AUTOSAR XML (schema 4-2-2)
package /STELLANTIS/EPT/ASWCs
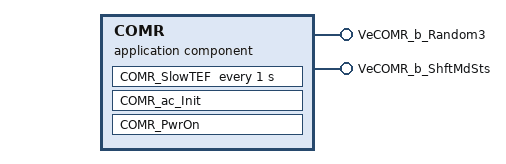
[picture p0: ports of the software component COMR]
  application sw component type COMR
    provide port VeCOMR_b_Random3: nonqueued-sender-com-spec{data-element=Value, init-value=0}, provided-interface=VeCOMR_b_Random3
    provide port VeCOMR_b_ShftMdSts: nonqueued-sender-com-spec{data-element=Value, init-value=0}, provided-interface=VeCOMR_b_ShftMdSts
    behavior IB_COMR: data-type-mapping=msADTtoIDTMapping, handle-termination-and-restart=NO-SUPPORT
      timing event Event_SlowTEF: start-on-event=COMR_SlowTEF, period=1
      init event Event_COMR_ac_Init: start-on-event=COMR_ac_Init
      init event Event_PwrOn: start-on-event=COMR_PwrOn
      runnable COMR_ac_Init
        data-send-points:
          access OUT_VeCOMR_b_ShftMdSts_Value: accessed-variable=VeCOMR_b_ShftMdSts.Value
      runnable COMR_PwrOn
        data-send-points:
          access OUT_VeCOMR_b_ShftMdSts_Value: accessed-variable=VeCOMR_b_ShftMdSts.Value
          access OUT_VeCOMR_b_Random3_Value: accessed-variable=VeCOMR_b_Random3.Value
      runnable COMR_SlowTEF
        data-send-points:
          access OUT_VeCOMR_b_Random3_Value: accessed-variable=VeCOMR_b_Random3.Value
